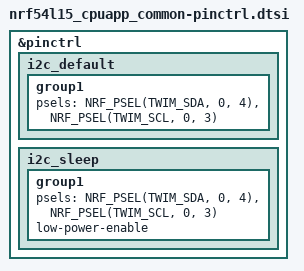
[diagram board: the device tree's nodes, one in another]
/*
 * Copyright (c) 2025 Daniel Kampert
 *
 * SPDX-License-Identifier: Apache-2.0
 */

&pinctrl {
    i2c_default: i2c_default {
        group1 {
            psels = <NRF_PSEL(TWIM_SDA, 0, 4)>,
                    <NRF_PSEL(TWIM_SCL, 0, 3)>;
        };
    };

    i2c_sleep: i2c_sleep {
        group1 {
            psels = <NRF_PSEL(TWIM_SDA, 0, 4)>,
                    <NRF_PSEL(TWIM_SCL, 0, 3)>;
            low-power-enable;
        };
    };
};
